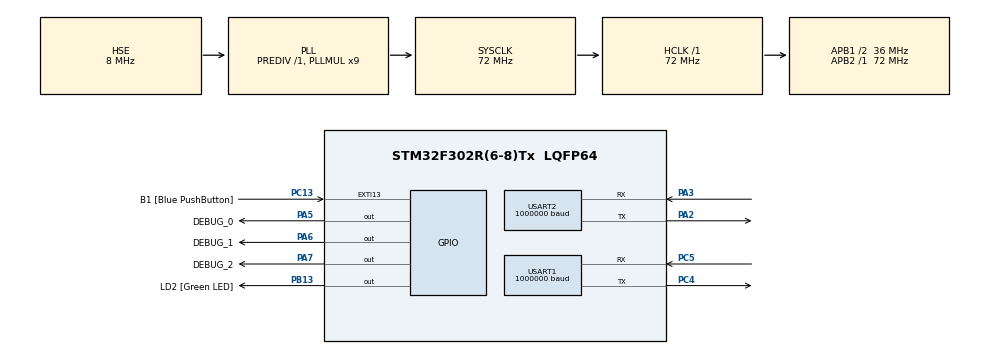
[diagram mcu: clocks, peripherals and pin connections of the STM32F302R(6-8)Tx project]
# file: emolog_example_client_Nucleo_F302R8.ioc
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Mcu.Family=STM32F3
Mcu.Name=STM32F302R(6-8)Tx
Mcu.Package=LQFP64
NVIC.PriorityGroup=NVIC_PRIORITYGROUP_0
NVIC.USART1_IRQn=true\:0\:0\:false\:false\:false
PA13.Mode=Serial_Wire
PA13.Signal=SYS_JTMS-SWDIO
PA14.Mode=Serial_Wire
PA14.Signal=SYS_JTCK-SWCLK
PA2.GPIO_Mode=GPIO_MODE_AF_PP
PA2.GPIO_PuPd=GPIO_NOPULL
PA2.GPIO_Speed=GPIO_SPEED_FREQ_HIGH
PA2.Mode=Asynchronous
PA2.Signal=USART2_TX
PA3.GPIO_Mode=GPIO_MODE_AF_PP
PA3.GPIO_PuPd=GPIO_NOPULL
PA3.GPIO_Speed=GPIO_SPEED_FREQ_HIGH
PA3.Mode=Asynchronous
PA3.Signal=USART2_RX
PA5.GPIO_Label=DEBUG_0
PA5.GPIO_PuPd=GPIO_PULLDOWN
PA5.GPIO_Speed=GPIO_SPEED_FREQ_LOW
PA5.PinState=GPIO_PIN_RESET
PA5.Signal=GPIO_Output
PA6.GPIO_Label=DEBUG_1
PA6.GPIO_PuPd=GPIO_PULLDOWN
PA6.GPIO_Speed=GPIO_SPEED_FREQ_LOW
PA6.PinState=GPIO_PIN_RESET
PA6.Signal=GPIO_Output
PA7.GPIO_Label=DEBUG_2
PA7.GPIO_PuPd=GPIO_PULLDOWN
PA7.GPIO_Speed=GPIO_SPEED_FREQ_LOW
PA7.PinState=GPIO_PIN_RESET
PA7.Signal=GPIO_Output
PB13.GPIO_Label=LD2 [Green LED]
PB13.GPIO_ModeDefaultOutputPP=GPIO_MODE_OUTPUT_PP
PB13.GPIO_PuPd=GPIO_NOPULL
PB13.GPIO_Speed=GPIO_SPEED_FREQ_LOW
PB13.PinState=GPIO_PIN_RESET
PB13.Signal=GPIO_Output
PB3.Signal=SYS_JTDO-TRACESWO
PC13.GPIO_Label=B1 [Blue PushButton]
PC13.GPIO_ModeDefaultEXTI=GPIO_MODE_IT_RISING
PC13.GPIO_PuPd=GPIO_NOPULL
PC13.Signal=GPXTI13
PC14\ -\ OSC32_IN.Signal=RCC_OSC32_IN
PC15\ -\ OSC32_OUT.Signal=RCC_OSC32_OUT
PC4.Mode=Asynchronous
PC4.Signal=USART1_TX
PC5.Mode=Asynchronous
PC5.Signal=USART1_RX
PF0-OSC_IN.Mode=HSE-External-Clock-Source
PF0-OSC_IN.Signal=RCC_OSC_IN
ProjectManager.HeapSize=0x200
ProjectManager.StackSize=0x400
ProjectManager.TargetToolchain=TrueSTUDIO
RCC.ADC12PRES=RCC_ADC1PLLCLK_DIV1
RCC.ADC34PRES=RCC_ADC34PLLCLK_DIV1
RCC.AHBCLKDivider=RCC_SYSCLK_DIV1
RCC.AHBFreq_Value=72000000
RCC.APB1CLKDivider=RCC_HCLK_DIV2
RCC.APB1Freq_Value=36000000
RCC.APB1TimFreq_Value=72000000
RCC.APB2CLKDivider=RCC_HCLK_DIV1
RCC.APB2Freq_Value=72000000
RCC.APB2TimFreq_Value=72000000
RCC.CortexFreq_Value=72000000
RCC.Cortex_Div=SYSTICK_CLKSOURCE_HCLK
RCC.FLatency=FLASH_LATENCY_2
RCC.HCLKFreq_Value=72000000
RCC.HSE_VALUE=8000000
RCC.HSI_VALUE=8000000
RCC.I2SClockSource=RCC_I2SCLKSOURCE_SYSCLK
RCC.I2c1ClockSelection=RCC_I2C1CLKSOURCE_HSI
RCC.I2c2ClockSelection=RCC_I2C2CLKSOURCE_HSI
RCC.I2c3ClockSelection=RCC_I2C3CLKSOURCE_HSI
RCC.LSEState=RCC_LSE_OFF
RCC.LSE_VALUE=32768
RCC.OscillatorTypeHSI=RCC_OSCILLATORTYPE_HSI
RCC.PLLMUL=RCC_PLL_MUL9
RCC.PLLSourceVirtual=RCC_PLLSOURCE_HSE
RCC.PREFETCH_ENABLE=1
RCC.PRESCALERUSB=RCC_USBCLKSOURCE_PLL
RCC.RCC_MCOMult_Clock_Source_FROM_PLLMUL=RCC_MCO1SOURCE_PLLCLK
RCC.RCC_MCOSource=RCC_MCO1SOURCE_SYSCLK
RCC.RCC_PLLsource_Clock_Source_FROM_HSE=RCC_HSE_PREDIV_DIV1
RCC.RTCClockSelection=RCC_RTCCLKSOURCE_LSI
RCC.SYSCLKFreq_VALUE=72000000
RCC.SYSCLKSourceVirtual=RCC_SYSCLKSOURCE_PLLCLK
RCC.USBFreq_Value=72000000
RCC.Uart4ClockSelection=RCC_UART4CLKSOURCE_PCLK1
RCC.Uart5ClockSelection=RCC_UART5CLKSOURCE_PCLK1
RCC.Usart1ClockSelection=RCC_USART1CLKSOURCE_PCLK1
RCC.Usart2ClockSelection=RCC_USART2CLKSOURCE_PCLK1
RCC.Usart3ClockSelection=RCC_USART3CLKSOURCE_PCLK1
USART1.BaudRate=1000000
USART1.VirtualMode-Asynchronous=VM_ASYNC
USART1.WordLength=WORDLENGTH_8B
USART2.BaudRate=1000000
USART2.DMADisableonRxErrorParam=UART_ADVFEATURE_DMA_ENABLEONRXERROR
USART2.VirtualMode-Asynchronous=VM_ASYNC
USART2.WordLength=WORDLENGTH_8B
board=NUCLEO-F302R8

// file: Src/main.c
/**
  ******************************************************************************
  * File Name          : main.c
  * Description        : Main program body
  ******************************************************************************
  ** This notice applies to any and all portions of this file
  * that are not between comment pairs USER CODE BEGIN and
  * USER CODE END. Other portions of this file, whether
  * inserted by the user or by software development tools
  * are owned by their respective copyright owners.
  *
  * COPYRIGHT(c) 2017 STMicroelectronics
  *
  * Redistribution and use in source and binary forms, with or without modification,
  * are permitted provided that the following conditions are met:
  *   1. Redistributions of source code must retain the above copyright notice,
  *      this list of conditions and the following disclaimer.
  *   2. Redistributions in binary form must reproduce the above copyright notice,
  *      this list of conditions and the following disclaimer in the documentation
  *      and/or other materials provided with the distribution.
  *   3. Neither the name of STMicroelectronics nor the names of its contributors
  *      may be used to endorse or promote products derived from this software
  *      without specific prior written permission.
  *
  * THIS SOFTWARE IS PROVIDED BY THE COPYRIGHT HOLDERS AND CONTRIBUTORS "AS IS"
  * AND ANY EXPRESS OR IMPLIED WARRANTIES, INCLUDING, BUT NOT LIMITED TO, THE
  * IMPLIED WARRANTIES OF MERCHANTABILITY AND FITNESS FOR A PARTICULAR PURPOSE ARE
  * DISCLAIMED. IN NO EVENT SHALL THE COPYRIGHT HOLDER OR CONTRIBUTORS BE LIABLE
  * FOR ANY DIRECT, INDIRECT, INCIDENTAL, SPECIAL, EXEMPLARY, OR CONSEQUENTIAL
  * DAMAGES (INCLUDING, BUT NOT LIMITED TO, PROCUREMENT OF SUBSTITUTE GOODS OR
  * SERVICES; LOSS OF USE, DATA, OR PROFITS; OR BUSINESS INTERRUPTION) HOWEVER
  * CAUSED AND ON ANY THEORY OF LIABILITY, WHETHER IN CONTRACT, STRICT LIABILITY,
  * OR TORT (INCLUDING NEGLIGENCE OR OTHERWISE) ARISING IN ANY WAY OUT OF THE USE
  * OF THIS SOFTWARE, EVEN IF ADVISED OF THE POSSIBILITY OF SUCH DAMAGE.
  *
  ******************************************************************************
  */
#include "main.h"
#include "stm32f3xx_hal.h"
#include "usart.h"
#include "gpio.h"

/* USER CODE BEGIN Includes */
#include "../../../examples/examples_common/emolog_example_client.h"
/* USER CODE END Includes */

/* USER CODE BEGIN PV */
/* Private variables ---------------------------------------------------------*/

/* USER CODE END PV */

void SystemClock_Config(void);

/* USER CODE BEGIN PFP */
/* Private function prototypes -----------------------------------------------*/
void delay_ms(uint32_t ms);
extern void USART1_IRQHandler(void);

/* USER CODE END PFP */

int main(void)
{

  /* MCU Configuration----------------------------------------------------------*/

  /* Reset of all peripherals, Initializes the Flash interface and the Systick. */
  HAL_Init();

  /* Configure the system clock */
  SystemClock_Config();

  /* Initialize all configured peripherals */
  MX_GPIO_Init();
  MX_USART2_UART_Init();
  MX_USART1_UART_Init();

  /* USER CODE BEGIN 2 */
  emolog_example_main_loop();  // never returns
  /* USER CODE END 2 */

  /* Infinite loop */
  while (1)
  {

  }

}

/** System Clock Configuration
*/
void SystemClock_Config(void)
{

  RCC_OscInitTypeDef RCC_OscInitStruct;
  RCC_ClkInitTypeDef RCC_ClkInitStruct;
  RCC_PeriphCLKInitTypeDef PeriphClkInit;

    /**Initializes the CPU, AHB and APB busses clocks
    */
  RCC_OscInitStruct.OscillatorType = RCC_OSCILLATORTYPE_HSI|RCC_OSCILLATORTYPE_HSE;
  RCC_OscInitStruct.HSEState = RCC_HSE_BYPASS;
  RCC_OscInitStruct.HSEPredivValue = RCC_HSE_PREDIV_DIV1;
  RCC_OscInitStruct.HSIState = RCC_HSI_ON;
  RCC_OscInitStruct.PLL.PLLState = RCC_PLL_ON;
  RCC_OscInitStruct.PLL.PLLSource = RCC_PLLSOURCE_HSE;
  RCC_OscInitStruct.PLL.PLLMUL = RCC_PLL_MUL9;
  if (HAL_RCC_OscConfig(&RCC_OscInitStruct) != HAL_OK)
  {
    _Error_Handler(__FILE__, __LINE__);
  }

    /**Initializes the CPU, AHB and APB busses clocks
    */
  RCC_ClkInitStruct.ClockType = RCC_CLOCKTYPE_HCLK|RCC_CLOCKTYPE_SYSCLK
                              |RCC_CLOCKTYPE_PCLK1|RCC_CLOCKTYPE_PCLK2;
  RCC_ClkInitStruct.SYSCLKSource = RCC_SYSCLKSOURCE_PLLCLK;
  RCC_ClkInitStruct.AHBCLKDivider = RCC_SYSCLK_DIV1;
  RCC_ClkInitStruct.APB1CLKDivider = RCC_HCLK_DIV2;
  RCC_ClkInitStruct.APB2CLKDivider = RCC_HCLK_DIV1;

  if (HAL_RCC_ClockConfig(&RCC_ClkInitStruct, FLASH_LATENCY_2) != HAL_OK)
  {
    _Error_Handler(__FILE__, __LINE__);
  }

  PeriphClkInit.PeriphClockSelection = RCC_PERIPHCLK_USART1;
  PeriphClkInit.Usart1ClockSelection = RCC_USART1CLKSOURCE_PCLK1;
  if (HAL_RCCEx_PeriphCLKConfig(&PeriphClkInit) != HAL_OK)
  {
    _Error_Handler(__FILE__, __LINE__);
  }

    /**Configure the Systick interrupt time
    */
  HAL_SYSTICK_Config(HAL_RCC_GetHCLKFreq()/1000);

    /**Configure the Systick
    */
  HAL_SYSTICK_CLKSourceConfig(SYSTICK_CLKSOURCE_HCLK);

  /* SysTick_IRQn interrupt configuration */
  HAL_NVIC_SetPriority(SysTick_IRQn, 0, 0);
}

/* USER CODE BEGIN 4 */
void delay_ms(uint32_t ms)
{
    HAL_Delay(ms);
}

/* USER CODE END 4 */

void _Error_Handler(char * file, int line)
{
  while(1)
  {
  }
}

/************************ (C) COPYRIGHT STMicroelectronics *****END OF FILE****/
